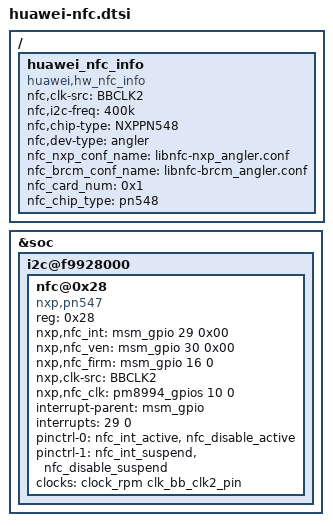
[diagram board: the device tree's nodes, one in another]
/* Copyright (c) 2014-2015, The Linux Foundation. All rights reserved.
 *
 * This program is free software; you can redistribute it and/or modify
 * it under the terms of the GNU General Public License version 2 and
 * only version 2 as published by the Free Software Foundation.
 *
 * This program is distributed in the hope that it will be useful,
 * but WITHOUT ANY WARRANTY; without even the implied warranty of
 * MERCHANTABILITY or FITNESS FOR A PARTICULAR PURPOSE.  See the
 * GNU General Public License for more details.
 */

 / {
	huawei_nfc_info {
		compatible = "huawei,hw_nfc_info";
		nfc,clk-src = "BBCLK2";
		nfc,i2c-freq = "400k";
		nfc,chip-type = "NXPPN548";
		nfc,dev-type = "angler";
		nfc_nxp_conf_name = "libnfc-nxp_angler.conf";
		nfc_brcm_conf_name = "libnfc-brcm_angler.conf";
		nfc_card_num = <0x1>;
		nfc_chip_type = "pn548";
		status = "ok";
	};
};

&soc {
	i2c@f9928000 { /* BLSP1 QUP6 */
		nfc@0x28 {
			compatible = "nxp,pn547";
			status = "ok";
			reg = <0x28>;
			nxp,nfc_int = <&msm_gpio 29 0x00>;
			nxp,nfc_ven = <&msm_gpio 30 0x00>;
			nxp,nfc_firm = <&msm_gpio 16 0>;
			nxp,clk-src = "BBCLK2";
			nxp,nfc_clk = <&pm8994_gpios 10 0>;
			interrupt-parent = <&msm_gpio>;
			interrupts = <29 0>;  /*1 = low-to-high edge triggered
						2 = high-to-low edge triggered
						4 = active high level-sensitive
						8 = active low level-sensitive */
			interrupt-names = "nfc_irq";
			pinctrl-names = "nfc_active","nfc_suspend";
			pinctrl-0 = <&nfc_int_active &nfc_disable_active>;
			pinctrl-1 = <&nfc_int_suspend &nfc_disable_suspend>;
			clocks = <&clock_rpm clk_bb_clk2_pin>;
			clock-names = "pn547_clk";
		};
	};
};

